# M55M1 register map
File version: 1.0
Registers are 32-bit, read-write, reset 0x0 unless marked. A register's access mark holds for its fields unless they carry their own. Offsets are from the block's base; [hi:lo] are bit positions; {n}, {i} and the like mark numbered series; 'fields as' and 'values as' point back to an identical list.

## CLK_NS — CLK Register Map
Base 0x50001000
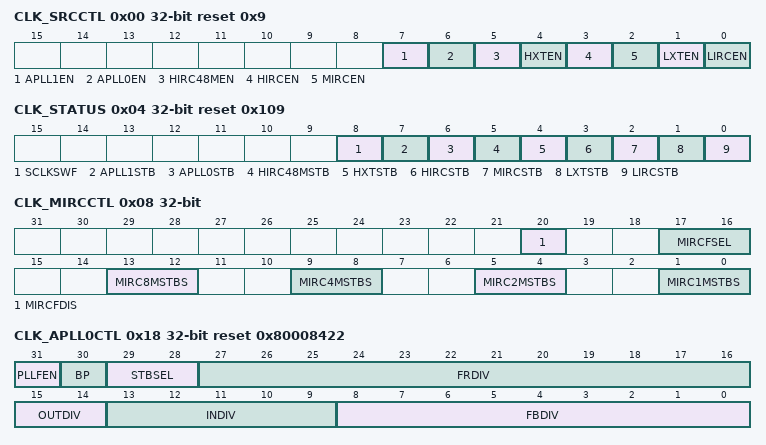
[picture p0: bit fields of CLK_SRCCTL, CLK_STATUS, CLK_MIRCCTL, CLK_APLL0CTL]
0x00 CLK_SRCCTL ro reset 0x9 — Clock Source Control Register
  [7] APLL1EN — APLL1 Enable Bit. Note : This bit is not retained when D2 power is turned off.
    0=APLL1 Disabled; 1=APLL1 Enabled
  [6] APLL0EN — APLL0 Enable Bit. Note : This bit is not retained when D2 power is turned off.
    0=APLL0 Disabled; 1=APLL0 Enabled
  [5] HIRC48MEN — HIRC48M Enable Bit. Note : This bit is not retained when D2 power is turned off.
    0=48 MHz internal high speed RC oscillator (HIRC48M) Disabled; 1=48 MHz internal high speed RC oscillator (HIRC48M) Enabled
  [4] HXTEN — HXT Enable Bit. Note : This bit is not retained when D2 power is turned off.
    0=4~32 MHz external high speed crystal (HXT) Disabled; 1=4~32 MHz external high speed crystal (HXT) Enabled
  [3] HIRCEN — HIRC Enable Bit. Note : This bit is not retained when D2 power is turned off.
    0=12 MHz internal high speed RC oscillator (HIRC) Disabled; 1=12 MHz internal high speed RC oscillator (HIRC) Enabled
  [2] MIRCEN — MIRC Enable Bit. Note : This bit is not retained when D2 power is turned off.
    0=1~8 MHz internal middle speed RC oscillator (MIRC) Disabled; 1=1~8 MHz internal middle speed RC oscillator (MIRC) Enabled
  [1] LXTEN — LXT Enable Bit. Note : This bit is not retained when D5 power is turned off.
    0=32.768 kHz external low speed crystal (LXT) Disabled; 1=32.768 kHz external low speed crystal (LXT) Enabled
  [0] LIRCEN — LIRC Enable Bit. Note : This bit is not retained when D4 power is turned off.
    0=32 kHz internal low speed RC oscillator (LIRC) Disabled; 1=32 kHz internal low speed RC oscillator (LIRC) Enabled
0x04 CLK_STATUS ro reset 0x109 — Clock Status Monitor Register
  [8] SCLKSWF — System Clock Switching Finish Flag (Read Only). This bit is updated when software switches system clock source. If switch target clock is stable, this bit will be set to 1. If switch target clock is not stable, this bit will be set to 0. Note 1: This bit is read only. After selected clock source is stable, hardware will switch system clock to selected clock automatically, and SCLKSWF will be setted automatically by hardware. Note 2: This bit is not retained when D0 power is turned off.
    0=Clock switching not finish; 1=Clock switching finish
  [7] APLL1STB — Internal APLL1 Clock Source Stable Flag (Read Only). Note: This bit is not retained when D0 power is turned off.
    0=Internal APLL1 clock is not stable or disabled; 1=Internal APLL1 clock is stable and enabled
  [6] APLL0STB — Internal APLL0 Clock Source Stable Flag (Read Only). Note: This bit is not retained when D0 power is turned off.
    0=Internal APLL0 clock is not stable or disabled; 1=Internal APLL0 clock is stable and enabled
  [5] HIRC48MSTB — HIRC48M Clock Source Stable Flag (Read Only). Note: This bit is not retained when D2 power is turned off.
    0=48 MHz internal high speed RC oscillator (HIRC48M) clock is not stable or disabled; 1=48 MHz internal high speed RC oscillator (HIRC48M) clock is stable and enabled
  [4] HXTSTB — HXT Clock Source Stable Flag (Read Only). Note: This bit is not retained when D2 power is turned off.
    0=4~32 MHz external high speed crystal oscillator (HXT) clock is not stable or disabled; 1=4~32 MHz external high speed crystal oscillator (HXT) clock is stable and enabled
  [3] HIRCSTB — HIRC Clock Source Stable Flag (Read Only). Note: This bit is not retained when D2 power is turned off.
    0=12 MHz internal high speed RC oscillator (HIRC) clock is not stable or disabled; 1=12 MHz internal high speed RC oscillator (HIRC) clock is stable and enabled
  [2] MIRCSTB — MIRC Clock Source Stable Flag (Read Only). Note: This bit is not retained when D2 power is turned off.
    0=Internal middle speed RC oscillator (MIRC) clock is not stable or disabled; 1=Internal middle speed RC oscillator (MIRC) clock is stable and enabled
  [1] LXTSTB — LXT Clock Source Stable Flag (Read Only). Note: This bit is not retained when D2 power is turned off.
    0=32.768 kHz external low speed crystal oscillator (LXT) clock is not stable or disabled; 1=32.768 kHz external low speed crystal oscillator (LXT) clock is stabled and enabled
  [0] LIRCSTB — LIRC Clock Source Stable Flag (Read Only). Note: This bit is not retained when D2 power is turned off.
    0=32 kHz internal low speed RC oscillator (LIRC) clock is not stable or disabled; 1=32 kHz internal low speed RC oscillator (LIRC) clock is stable and enabled
0x08 CLK_MIRCCTL ro — MIRC Control Register
  [20] MIRCFDIS — MIRC Clock Filter Disable Bit. Note: This bit is not retained when D2 power is turned off.
    0=MIRC Filter enabled; 1=MIRC Filter disabled
  [17:16] MIRCFSEL — MIRC Frequency Select Bits. Note: These bits are not retained when D2 power is turned off.
    0=Internal middle speed RC oscillator frequency is 1 MHz; 1=Internal middle speed RC oscillator frequency is 2 MHz; 2=Internal middle speed RC oscillator frequency is 4 MHz; 3=Internal middle speed RC oscillator frequency is 8 MHz
  [13:12] MIRC8MSTBS — MIRC8M Stable Count Select. Note: These bits are not retained when D2 power is turned off.
    0=MIRC8M stable count is 24 clocks and clock output deviation about 2%; 1=MIRC8M stable count is 21 clocks and clock output deviation about 5%
  [9:8] MIRC4MSTBS — MIRC4M Stable Count Select. Note: These bits are not retained when D2 power is turned off.
    0=MIRC4M stable count is 12 clocks and clock output deviation about 2%; 1=MIRC4M stable count is 10 clocks and clock output deviation about 5%
  [5:4] MIRC2MSTBS — MIRC2M Stable Count Select. Note: These bits are not retained when D2 power is turned off.
    0=MIRC2M stable count is 10 clocks and clock output deviation about 2%; 1=MIRC2M stable count is 6 clocks and clock output deviation about 5%
  [1:0] MIRC1MSTBS — MIRC1M Stable Count Select. Note: These bits are not retained when D2 power is turned off.
    0=MIRC1M stable count is 9 clocks and clock output deviation about 2%; 1=MIRC1M stable count is 8 clocks and clock output deviation about 5%
0x18 CLK_APLL0CTL ro reset 0x80008422 — APLL0 Control Register
  [31] PLLFEN — APLL0 Clock Filter Enable Bit. Note: This bit is not retained when D2 power is turned off.
    0=APLL0 Filter Disable; 1=APLL0 Filter Enable
  [30] BP — APLL0 Bypass Control. Note: This bit is not retained when D2 power is turned off.
    0=APLL0 is in normal mode (default); 1=APLL0 clock output is same as APLL0 input clock FIN
  [29:28] STBSEL — APLL0 Stable Counter Selection. Note: These bits are not retained when D2 power is turned off.
    0=APLL0 stable time is 820 APLL0 source clock (source clock is equal to 4M); 1=APLL0 stable time is 2460 APLL0 source clock (4 MHz source clock ≤12 MHz); 2=APLL0 stable time is 4920 APLL0 source clock (12 MHz source clock ≤24 MHz)
  [27:16] FRDIV — APLL0 Fractional Divider Control. Refer to the formulas below the table. Note: These bits are not retained when D2 power is turned off.
  [15:14] OUTDIV — APLL0 Output Divider Control. Refer to the formulas below the table. Note: These bits are not retained when D2 power is turned off.
  [13:9] INDIV — APLL0 Input Divider Control. Refer to the formulas below the table. Note: These bits are not retained when D2 power is turned off.
  [8:0] FBDIV — APLL0 Feedback Divider Control. Refer to the formulas below the table. Note: These bits are not retained when D2 power is turned off.
0x1C CLK_APLL0SEL ro — APLL0 Clock Source Select Control Register
  [1:0] APLLSRC — APLL0 Source Clock Selection. Note: These bits are not retained when D2 power is turned off.
    0=APLL0 source clock from 4~24 MHz external high-speed crystal oscillator (HXT); 1=APLL0 source clock from 24~32 MHz external high-speed crystal oscillator (HXT/2); 2=APLL0 source clock from 12 MHz internal high-speed oscillator (HIRC); 3=APLL0 source clock from 48 MHz internal high-speed oscillator (HIRC48M/4)
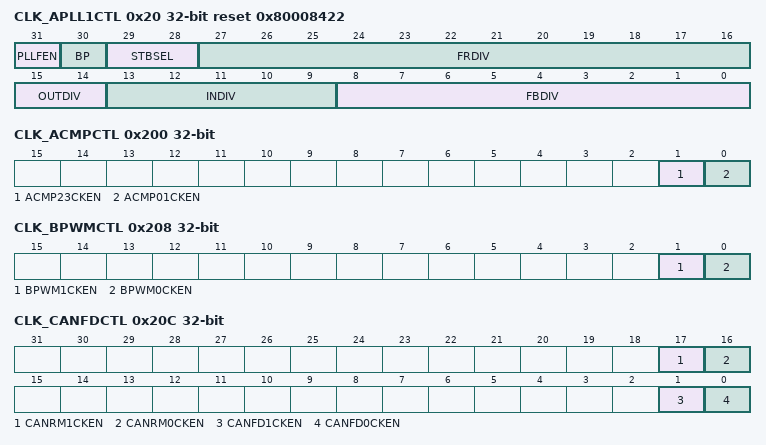
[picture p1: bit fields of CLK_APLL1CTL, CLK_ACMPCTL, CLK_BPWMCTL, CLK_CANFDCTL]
0x20 CLK_APLL1CTL ro reset 0x80008422 — APLL1 Control Register
  [31] PLLFEN — APLL1 Clock Filter Enable Bit. Note: This bit is not retained when D2 power is turned off.
    0=APLL1 Filter Disable; 1=APLL1 Filter Enable
  [30] BP — APLL1 Bypass Control. Note: This bit is not retained when D2 power is turned off.
    0=APLL1 is in normal mode (default); 1=APLL1 clock output is same as APLL1 input clock FIN
  [29:28] STBSEL — APLL1 Stable Counter Selection. Note 1: These bits are not retained when D2 power is turned off.
    0=APLL1 stable time is 820 APLL1 source clock (source clock is equal to 4M); 1=APLL1 stable time is 2460 APLL1 source clock (4 MHz source clock ≤12 MHz); 2=APLL1 stable time is 4920 APLL1 source clock (12 MHz source clock ≤24 MHz)
  [27:16] FRDIV — APLL1 Fractional Divider Control. Refer to the formulas below the table. Note: These bits are not retained when D2 power is turned off.
  [15:14] OUTDIV — APLL1 Output Divider Control. Refer to the formulas below the table. Note: These bits are not retained when D2 power is turned off.
  [13:9] INDIV — APLL1 Input Divider Control. Refer to the formulas below the table. Note: These bits are not retained when D2 power is turned off.
  [8:0] FBDIV — APLL1 Feedback Divider Control. Refer to the formulas below the table. Note: These bits are not retained when D2 power is turned off.
0x24 CLK_APLL1SEL ro — APLL1 Clock Source Select Control Register
  [1:0] APLLSRC — APLL1 Source Clock Selection. Note : These bits are not retained when D2 power is turned off.
    0=APLL1 source clock from 4~24 MHz external high-speed crystal oscillator (HXT); 1=APLL1 source clock from 24~32 MHz external high-speed crystal oscillator (HXT/2); 2=APLL1 source clock from 12 MHz internal high-speed oscillator (HIRC); 3=APLL1 source clock from 48 MHz internal high-speed oscillator (HIRC48M/4)
0x200 CLK_ACMPCTL ro — ACMP Clock Enable Control Register
  [1] ACMP23CKEN — ACMP2/3 Clock Enable Bit. Note: This bit is not retained when D0 power is turned off.
    0=ACMP2/3 clock Disabled; 1=ACMP2/3 clock Enabled
  [0] ACMP01CKEN — ACMP0/1 Clock Enable Bit. Note: This bit is not retained when D0 power is turned off.
    0=ACMP0/1 clock Disabled; 1=ACMP0/1 clock Enabled
0x204 CLK_AWFCTL ro — AWF Clock Enable Control Register
  [0] AWF0CKEN — AWFx Clock Enable Bit. Note: This bit is not retained when D0 power is turned off.
    0=AWFx clock Disabled; 1=AWFx clock Enabled
0x208 CLK_BPWMCTL ro — BPWM Clock Enable Control Register
  [1] BPWM1CKEN — BPWMx Clock Enable Bit. Note: This bit is not retained when D0 power is turned off.
    0=BPWMx clock Disabled; 1=BPWMx clock Enabled
  [0] BPWM0CKEN — BPWMx Clock Enable Bit. Note: This bit is not retained when D0 power is turned off.
    0=BPWMx clock Disabled; 1=BPWMx clock Enabled
0x20C CLK_CANFDCTL ro — CANFD Clock Enable Control Register
  [17] CANRM1CKEN — CANFD1 Message SRAM Clock Enable Bit. Note: This bit is not retained when D0 power is turned off.
    0=CANFD1 Message SRAM clock Disabled; 1=CANFD1 Message SRAM clock Enabled
  [16] CANRM0CKEN — CANFD0 Message SRAM Clock Enable Bit. Note: This bit is not retained when D0 power is turned off.
    0=CANFD0 Message SRAM clock Disabled; 1=CANFD0 Message SRAM clock Enabled
  [1] CANFD1CKEN — CANFDx Clock Enable Bit. Note: This bit is not retained when D0 power is turned off.
    0=CANFDx clock Disabled; 1=CANFDx clock Enabled
  [0] CANFD0CKEN — CANFDx Clock Enable Bit. Note: This bit is not retained when D0 power is turned off.
    0=CANFDx clock Disabled; 1=CANFDx clock Enabled
0x210 CLK_CCAPCTL ro — CCAP Clock Enable Control Register
  [0] CCAP0CKEN — CCAPx Clock Enable Bit. Note: This bit is not retained when D0 power is turned off.
    0=CCAPx clock Disabled; 1=CCAPx clock Enabled
0x214 CLK_CRCCTL ro — CRC Clock Enable Control Register
  [0] CRC0CKEN — CRCx Clock Enable Bit. Note: This bit is not retained when D0 power is turned off.
    0=CRCx clock Disabled; 1=CRCx clock Enabled
0x218 CLK_CRYPTOCTL ro — CRYPTO Clock Enable Control Register
  [0] CRYPTO0CKEN — CRYPTOx Clock Enable Bit. Note: This bit is not retained when D0 power is turned off.
    0=CRYPTOx clock Disabled; 1=CRYPTOx clock Enabled
0x21C CLK_DACCTL ro — DAC Clock Enable Control Register
  [0] DAC01CKEN — DAC0/DAC1 Clock Enable Bit. Note: This bit is not retained when D0 power is turned off.
    0=DAC0/1 clock Disabled; 1=DAC0/1 clock Enabled
0x220 CLK_DMICCTL ro — DMIC Clock Enable Control Register
  [0] DMIC0CKEN — DMICx Clock Enable Bit. Note: This bit is not retained when D2 power is turned off.
    0=DMICx clock Disabled; 1=DMICx clock Enabled
0x224 CLK_EADCCTL ro — EADC Clock Enable Control Register
  [0] EADC0CKEN — EADCx Clock Enable Bit. Note: This bit is not retained when D0 power is turned off.
    0=EADCx clock Disabled; 1=EADCx clock Enabled
0x228 CLK_EBICTL ro — EBI Clock Enable Control Register
  [0] EBI0CKEN — EBIx Clock Enable Bit. Note: This bit is not retained when D0 power is turned off.
    0=EBIx clock Disabled; 1=EBIx clock Enabled
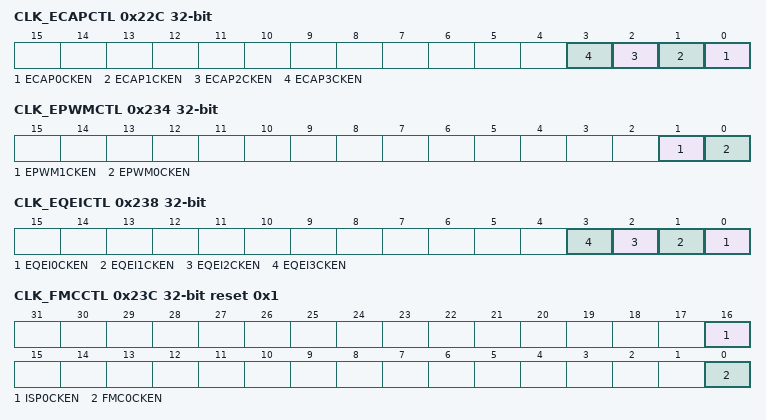
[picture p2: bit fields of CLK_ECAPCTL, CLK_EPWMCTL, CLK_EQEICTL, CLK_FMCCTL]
0x22C CLK_ECAPCTL ro — ECAP Clock Enable Control Register
  [all] fields
    0=ECAPx clock Disabled; 1=ECAPx clock Enabled
  [n] ECAP{n}CKEN (n=0..3) — ECAPx Clock Enable Bit. Note: This bit is not retained when D0 power is turned off.
0x230 CLK_EMACCTL ro — EMAC Clock Enable Control Register
  [0] EMAC0CKEN — EMACx Clock Enable Bit. Note: This bit is not retained when D0 power is turned off.
    0=EMACx clock Disabled; 1=EMACx clock Enabled
0x234 CLK_EPWMCTL ro — EPWM Clock Enable Control Register
  [1] EPWM1CKEN — EPWMx Clock Enable Bit. Note: This bit is not retained when D0 power is turned off.
    0=EPWMx clock Disabled; 1=EPWMx clock Enabled
  [0] EPWM0CKEN — EPWMx Clock Enable Bit. Note: This bit is not retained when D0 power is turned off.
    0=EPWMx clock Disabled; 1=EPWMx clock Enabled
0x238 CLK_EQEICTL ro — EQEI Clock Enable Control Register
  [all] fields
    0=EQEIx clock Disabled; 1=EQEIx clock Enabled
  [n] EQEI{n}CKEN (n=0..3) — EQEIx Clock Enable Bit. Note: This bit is not retained when D0 power is turned off.
0x23C CLK_FMCCTL ro reset 0x1 — FMC Clock Enable Control Register
  [16] ISP0CKEN — ISPx Clock Enable Bit. Note: This bit is not retained when D0 power is turned off.
    0=ISPx clock Disabled; 1=ISPx clock Enabled
  [0] FMC0CKEN — FMCx Clock Enable Bit. Note: This bit is not retained when D0 power is turned off.
    0=FMC clock Disabled when chip is under IDLE mode; 1=FMC clock Enabled when chip is under IDLE mode
0x240 CLK_GDMACTL ro — GDMA Clock Enable Control Register
  [0] GDMA0CKEN — GDMAx Clock Enable Bit. Note: This bit is not retained when D0 power is turned off.
    0=GDMAx clock Disabled; 1=GDMAx clock Enabled
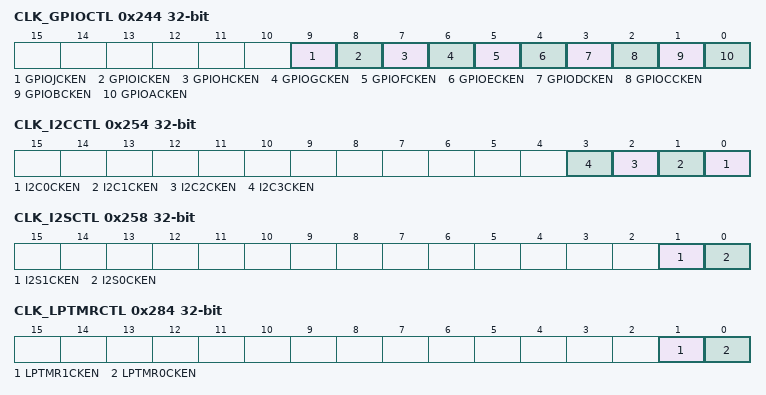
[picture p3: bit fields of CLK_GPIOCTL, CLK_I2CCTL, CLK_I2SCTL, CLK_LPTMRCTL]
0x244 CLK_GPIOCTL ro — GPIO Clock Enable Control Register
  [9] GPIOJCKEN — GPIOJ Clock Enable Bit. Note: This bit is not retained when D0 power is turned off.
    0=GPIOJ clock Disabled; 1=GPIOJ clock Enabled
  [8] GPIOICKEN — GPIOI Clock Enable Bit. Note: This bit is not retained when D0 power is turned off.
    0=GPIOI clock Disabled; 1=GPIOI clock Enabled
  [7] GPIOHCKEN — GPIOH Clock Enable Bit. Note: This bit is not retained when D0 power is turned off.
    0=GPIOH clock Disabled; 1=GPIOH clock Enabled
  [6] GPIOGCKEN — GPIOG Clock Enable Bit. Note: This bit is not retained when D0 power is turned off.
    0=GPIOG clock Disabled; 1=GPIOG clock Enabled
  [5] GPIOFCKEN — GPIOF Clock Enable Bit. Note: This bit is not retained when D0 power is turned off.
    0=GPIOF clock Disabled; 1=GPIOF clock Enabled
  [4] GPIOECKEN — GPIOE Clock Enable Bit. Note: This bit is not retained when D0 power is turned off.
    0=GPIOE clock Disabled; 1=GPIOE clock Enabled
  [3] GPIODCKEN — GPIOD Clock Enable Bit. Note: This bit is not retained when D0 power is turned off.
    0=GPIOD clock Disabled; 1=GPIOD clock Enabled
  [2] GPIOCCKEN — GPIOC Clock Enable Bit. Note: This bit is not retained when D0 power is turned off.
    0=GPIOC clock Disabled; 1=GPIOC clock Enabled
  [1] GPIOBCKEN — GPIOB Clock Enable Bit. Note: This bit is not retained when D0 power is turned off.
    0=GPIOB clock Disabled; 1=GPIOB clock Enabled
  [0] GPIOACKEN — GPIOA Clock Enable Bit. Note: This bit is not retained when D0 power is turned off.
    0=GPIOA clock Disabled; 1=GPIOA clock Enabled
0x248 CLK_HSOTGCTL ro — HSOTG Clock Enable Control Register
  [0] HSOTG0CKEN — HSOTGx Clock Enable Bit. Note: This bit is not retained when D0 power is turned off.
    0=HSOTGx clock Disabled; 1=HSOTGx clock Enabled
0x24C CLK_HSUSBDCTL ro — HSUSBD Clock Enable Control Register
  [0] HSUSBD0CKEN — HSUSBDx Clock Enable Bit. Note: This bit is not retained when D0 power is turned off.
    0=HSUSBDx clock Disabled; 1=HSUSBDx clock Enabled
0x250 CLK_HSUSBHCTL ro — HSUSBH Clock Enable Control Register
  [0] HSUSBH0CKEN — HSUSBHx Clock Enable Bit. Note: This bit is not retained when D0 power is turned off.
    0=HSUSBHx clock Disabled; 1=HSUSBHx clock Enabled
0x254 CLK_I2CCTL ro — I2C Clock Enable Control Register
  [all] fields
    0=I2Cx clock Disabled; 1=I2Cx clock Enabled
  [n] I2C{n}CKEN (n=0..3) — I2Cx Clock Enable Bit. Note: This bit is not retained when D0 power is turned off.
0x258 CLK_I2SCTL ro — I2S Clock Enable Control Register
  [1] I2S1CKEN — I2Sx Clock Enable Bit. Note: This bit is not retained when D0 power is turned off.
    0=I2Sx clock Disabled; 1=I2Sx clock Enabled
  [0] I2S0CKEN — I2Sx Clock Enable Bit. Note: This bit is not retained when D0 power is turned off.
    0=I2Sx clock Disabled; 1=I2Sx clock Enabled
0x25C CLK_I3CCTL ro — I3C Clock Enable Control Register
  [0] I3C0CKEN — I3Cx Clock Enable Bit. Note: This bit is not retained when D0 power is turned off.
    0=I3Cx clock Disabled; 1=I3Cx clock Enabled
0x260 CLK_KDFCTL ro — KDF Clock Enable Control Register
  [0] KDF0CKEN — KDFx Clock Enable Bit. Note: This bit is not retained when D0 power is turned off.
    0=KDFx clock Disabled; 1=KDFx clock Enabled
0x264 CLK_KPICTL ro — KPI Clock Enable Control Register
  [0] KPI0CKEN — KPIx Clock Enable Bit. Note: This bit is not retained when D0 power is turned off.
    0=KPIx clock Disabled; 1=KPIx clock Enabled
0x268 CLK_KSCTL ro — KS Clock Enable Control Register
  [0] KS0CKEN — KSx Clock Enable Bit. Note: This bit is not retained when D0 power is turned off.
    0=KSx clock Disabled; 1=KSx clock Enabled
0x26C CLK_LPADCCTL ro — Low Power ADC Clock Enable Control Register
  [0] LPADC0CKEN — LPADCx Clock Enable Bit. Note: This bit is not retained when D0 power is turned off.
    0=LPADCx clock Disabled; 1=LPADCx clock Enabled
0x270 CLK_LPPDMACTL ro — Low Power PDMA Clock Enable Control Register
  [0] LPPDMA0CKEN — LPPDMAx Clock Enable Bit. Note: This bit is not retained when D0 power is turned off.
    0=LPPDMAx clock Disabled; 1=LPPDMAx clock Enabled
0x274 CLK_LPGPIOCTL ro — Low Power GPIO Clock Enable Control Register
  [0] LPGPIO0CKEN — LPGPIOx Clock Enable Bit. Note: This bit is not retained when D0 power is turned off.
    0=LPGPIOx clock Disabled; 1=LPGPIOx clock Enabled
0x278 CLK_LPI2CCTL ro — Low Power I2C Clock Enable Control Register
  [0] LPI2C0CKEN — LPI2Cx Clock Enable Bit. Note: This bit is not retained when D0 power is turned off.
    0=LPI2Cx clock Disabled; 1=LPI2Cx clock Enabled
0x27C CLK_LPSPICTL ro — Low Power SPI Clock Enable Control Register
  [0] LPSPI0CKEN — LPSPIx Clock Enable Bit. Note: This bit is not retained when D0 power is turned off.
    0=LPSPIx clock Disabled; 1=LPSPIx clock Enabled
0x280 CLK_LPSRAMCTL ro — Low Power SRAM Clock Enable Control Register
  [0] LPSRAM0CKEN — LPSRAMx Clock Enable Bit. Note: This bit is not retained when D0 power is turned off.
    0=LPSRAMx clock Disabled; 1=LPSRAMx clock Enabled
0x284 CLK_LPTMRCTL ro — Low Power Timer Clock Enable Control Register
  [1] LPTMR1CKEN — LPTMRx Clock Enable Bit. Note: This bit is not retained when D0 power is turned off.
    0=LPTMRx clock Disabled; 1=LPTMRx clock Enabled
  [0] LPTMR0CKEN — LPTMRx Clock Enable Bit. Note: This bit is not retained when D0 power is turned off.
    0=LPTMRx clock Disabled; 1=LPTMRx clock Enabled
0x288 CLK_LPUARTCTL ro — Low Power UART Clock Enable Control Register
  [0] LPUART0CKEN — LPUARTx Clock Enable Bit. Note: This bit is not retained when D0 power is turned off.
    0=LPUARTx clock Disabled; 1=LPUARTx clock Enabled
0x28C CLK_NPUCTL ro — NPU Clock Enable Control Register
  [0] NPU0CKEN — NPUx Clock Enable Bit. Note: This bit is not retained when D0 power is turned off.
    0=NPUx clock Disabled; 1=NPUx clock Enabled
0x294 CLK_OTFCCTL ro — OTFC Clock Enable Control Register
  [0] OTFC0CKEN — OTFCx Clock Enable Bit. Note: This bit is not retained when D0 power is turned off.
    0=OTFCx clock Disabled; 1=OTFCx clock Enabled
0x298 CLK_OTGCTL ro — OTG Clock Enable Control Register
  [0] OTG0CKEN — OTGx Clock Enable Bit. Note: This bit is not retained when D0 power is turned off.
    0=OTGx clock Disabled; 1=OTGx clock Enabled
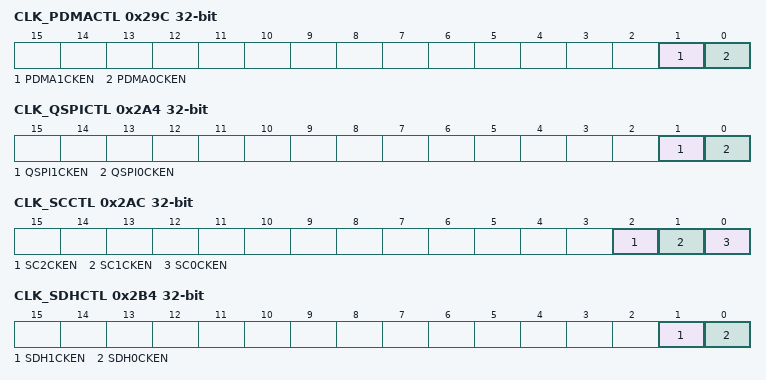
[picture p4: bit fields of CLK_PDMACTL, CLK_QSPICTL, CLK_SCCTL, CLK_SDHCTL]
0x29C CLK_PDMACTL ro — PDMA Clock Enable Control Register
  [1] PDMA1CKEN — PDMAx Clock Enable Bit. Note: This bit is not retained when D0 power is turned off.
    0=PDMAx clock Disabled; 1=PDMAx clock Enabled
  [0] PDMA0CKEN — PDMAx Clock Enable Bit. Note: This bit is not retained when D0 power is turned off.
    0=PDMAx clock Disabled; 1=PDMAx clock Enabled
0x2A0 CLK_PSIOCTL ro — PSIO Clock Enable Control Register
  [0] PSIO0CKEN — PSIOx Clock Enable Bit. Note: This bit is not retained when D0 power is turned off.
    0=PSIOx clock Disabled; 1=PSIOx clock Enabled
0x2A4 CLK_QSPICTL ro — QSPI Clock Enable Control Register
  [1] QSPI1CKEN — QSPIx Clock Enable Bit. Note: This bit is not retained when D0 power is turned off.
    0=QSPIx clock Disabled; 1=QSPIx clock Enabled
  [0] QSPI0CKEN — QSPIx Clock Enable Bit. Note: This bit is not retained when D0 power is turned off.
    0=QSPIx clock Disabled; 1=QSPIx clock Enabled
0x2A8 CLK_RTCCTL ro — RTC Clock Enable Control Register
  [0] RTC0CKEN — RTCx Clock Enable Bit. Note: This bit is not retained when D0 power is turned off.
    0=RTCx clock Disabled; 1=RTCx clock Enabled
0x2AC CLK_SCCTL ro — SC Clock Enable Control Register
  [all] fields
    0=SCx clock Disabled; 1=SCx clock Enabled
  [2] SC2CKEN — SCx Clock Enable Bit. Note: This bit is not retained when D0 power is turned off.
  [1] SC1CKEN — SCx Clock Enable Bit. Note: This bit is not retained when D0 power is turned off.
  [0] SC0CKEN — SCx Clock Enable Bit. Note: This bit is not retained when D0 power is turned off.
0x2B0 CLK_SCUCTL ro reset 0x1 — SCU Clock Enable Control Register
  [0] SCU0CKEN — SCUx Clock Enable Bit. Note: This bit is not retained when D0 power is turned off.
    0=SCUx clock Disabled; 1=SCUx clock Enabled
0x2B4 CLK_SDHCTL ro — SDH Clock Enable Control Register
  [1] SDH1CKEN — SDHx Clock Enable Bit. Note: This bit is not retained when D0 power is turned off.
    0=SDHx clock Disabled; 1=SDHx clock Enabled
  [0] SDH0CKEN — SDHx Clock Enable Bit. Note: This bit is not retained when D0 power is turned off.
    0=SDHx clock Disabled; 1=SDHx clock Enabled
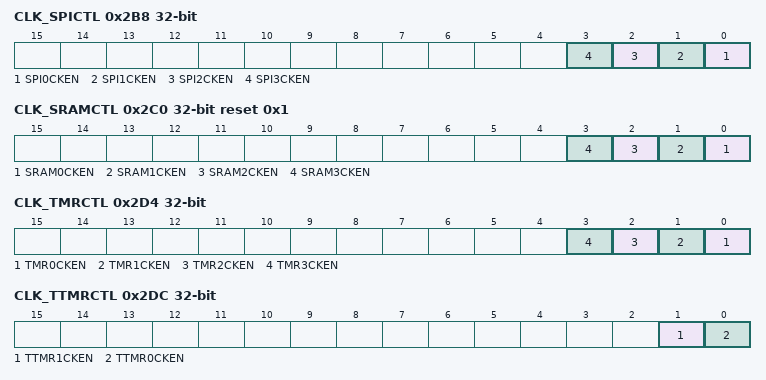
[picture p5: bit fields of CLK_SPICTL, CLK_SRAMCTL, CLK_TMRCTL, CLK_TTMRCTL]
0x2B8 CLK_SPICTL ro — SPI Clock Enable Control Register
  [all] fields
    0=SPIx clock Disabled; 1=SPIx clock Enabled
  [n] SPI{n}CKEN (n=0..3) — SPIx Clock Enable Bit. Note: This bit is not retained when D0 power is turned off.
0x2BC CLK_SPIMCTL ro — SPIM Clock Enable Control Register
  [0] SPIM0CKEN — SPIMx Clock Enable Bit. Note: This bit is not retained when D0 power is turned off.
    0=SPIMx clock Disabled; 1=SPIMx clock Enabled
0x2C0 CLK_SRAMCTL ro reset 0x1 — System SRAM Clock Enable Control Register
  [all] fields
    0=SRAMx clock Disabled; 1=SRAMx clock Enabled
  [n] SRAM{n}CKEN (n=0..3) — SRAMx Clock Enable Bit. Note: This bit is not retained when D0 power is turned off.
0x2CC CLK_STCTL ro — System Tick Clock Enable Control Register
  [0] ST0CKEN — SYSTICKx Clock Enable Bit. Note: This bit is not retained when D0 power is turned off.
    0=SYSTICKx clock Disabled; 1=SYSTICKx clock Enabled
0x2D4 CLK_TMRCTL ro — Timer Clock Enable Control Register
  [all] fields
    0=TIMERx clock Disabled; 1=TIMERx clock Enabled
  [n] TMR{n}CKEN (n=0..3) — TIMERx Clock Enable Bit. Note: This bit is not retained when D0 power is turned off.
0x2D8 CLK_TRNGCTL ro — TRNG Clock Enable Control Register
  [0] TRNG0CKEN — TRNGx Clock Enable Bit. Note: This bit is not retained when D0 power is turned off.
    0=TRNGx clock Disabled; 1=TRNGx clock Enabled
0x2DC CLK_TTMRCTL ro — Tick Timer Clock Enable Control Register
  [1] TTMR1CKEN — TTMRx Clock Enable Bit. Note: This bit is not retained when D2 power is turned off.
    0=TTMRx clock Disabled; 1=TTMRx clock Enabled
  [0] TTMR0CKEN — TTMRx Clock Enable Bit. Note: This bit is not retained when D2 power is turned off.
    0=TTMRx clock Disabled; 1=TTMRx clock Enabled
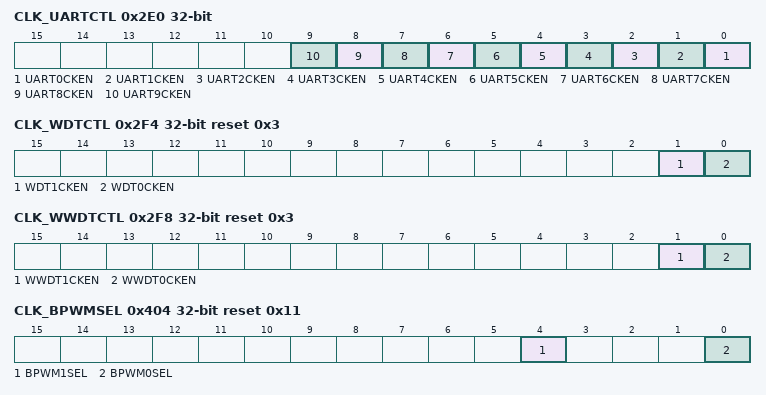
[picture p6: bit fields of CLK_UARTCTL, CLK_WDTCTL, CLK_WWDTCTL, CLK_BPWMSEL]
0x2E0 CLK_UARTCTL ro — UART Clock Enable Control Register
  [all] fields
    0=UARTx clock Disabled; 1=UARTx clock Enabled
  [n] UART{n}CKEN (n=0..9) — UARTx Clock Enable Bit. Note: This bit is not retained when D0 power is turned off.
0x2E4 CLK_USBDCTL ro — USBD Clock Enable Control Register
  [0] USBD0CKEN — USBDx Clock Enable Bit. Note: This bit is not retained when D0 power is turned off.
    0=USBDx clock Disabled; 1=USBDx clock Enabled
0x2E8 CLK_USBHCTL ro — USBH Clock Enable Control Register
  [0] USBH0CKEN — USBHx Clock Enable Bit. Note: This bit is not retained when D0 power is turned off.
    0=USBHx clock Disabled; 1=USBHx clock Enabled
0x2EC CLK_USCICTL ro — USCI Clock Enable Control Register
  [0] USCI0CKEN — USCIx Clock Enable Bit. Note: This bit is not retained when D0 power is turned off.
    0=USCIx clock Disabled; 1=USCIx clock Enabled
0x2F0 CLK_UTCPDCTL ro — UTCPD Clock Enable Control Register
  [0] UTCPD0CKEN — UTCPDx Clock Enable Bit. Note: This bit is not retained when D0 power is turned off.
    0=UTCPDx clock Disabled; 1=UTCPDx clock Enabled
0x2F4 CLK_WDTCTL ro reset 0x3 — WDT Clock Enable Control Register
  [1] WDT1CKEN — WDTx Clock Enable Bit. Note 2: This bit is not retained when D2 power is turned off.
    0=WDTx clock Disabled; 1=WDTx clock Enabled
  [0] WDT0CKEN — WDTx Clock Enable Bit. Note 2: This bit is not retained when D2 power is turned off.
    0=WDTx clock Disabled; 1=WDTx clock Enabled
0x2F8 CLK_WWDTCTL ro reset 0x3 — WWDT Clock Enable Control Register
  [1] WWDT1CKEN — WWDTx Clock Enable Bit. Note 2: This bit is not retained when D0 power is turned off.
    0=WWDTx clock Disabled; 1=WWDTx clock Enabled
  [0] WWDT0CKEN — WWDTx Clock Enable Bit. Note 2: This bit is not retained when D0 power is turned off.
    0=WWDTx clock Disabled; 1=WWDTx clock Enabled
0x400 CLK_SCLKSEL ro — System Clock Source Select Control Register
  [2:0] SCLKSEL — System Clock Source Selection. The system clock source is defined by SCLKSEL. Note: These bits are not retained when D2 power is turned off.
    0=Clock source from HIRC; 1=Clock source from MIRC; 2=Clock source from HIRC48M; 3=Clock source from HXT; 4=Clock source from APLL0
0x404 CLK_BPWMSEL ro reset 0x11 — BPWM Clock Source Select Control Register
  [4] BPWM1SEL — BPWM1 Clock Source Selection. The peripheral clock source of BPWM1 is defined by BPWM1SEL. Note: This bit is not retained when D1 power is turned off.
    0=Clock source from PCLK2; 1=Clock source from HCLK0
  [0] BPWM0SEL — BPWM0 Clock Source Selection. The peripheral clock source of BPWM0 is defined by BPWM0SEL. Note: This bit is not retained when D1 power is turned off.
    0=Clock source from PCLK0; 1=Clock source from HCLK0
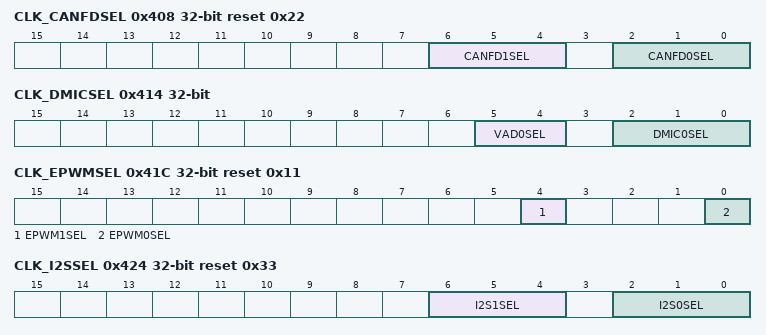
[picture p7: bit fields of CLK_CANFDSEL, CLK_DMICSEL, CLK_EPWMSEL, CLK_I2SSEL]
0x408 CLK_CANFDSEL ro reset 0x22 — CANFD Clock Source Select Control Register
  [6:4] CANFD1SEL — CANFD1 Clock Source Selection. The peripheral clock source of CANFD1 is defined by CANFD1SEL. Note: These bits are not retained when D1 power is turned off.
    0=Clock source from HXT; 1=Clock source from APLL0/2; 2=Clock source from HCLK0; 3=Clock source from HIRC; 4=Clock source from HIRC48M/4
  [2:0] CANFD0SEL — CANFD0 Clock Source Selection. The peripheral clock source of CANFD0 is defined by CANFD0SEL. Note: These bits are not retained when D1 power is turned off.
    values as CANFD1SEL
0x40C CLK_CCAPSEL ro reset 0x1 — CCAP Clock Source Select Control Register
  [2:0] CCAP0SEL — CCAP Sensor Clock Source Selection. The peripheral clock source of CCAP is defined by CCAP0SEL. Note: These bits are not retained when D2 power is turned off.
    0=Clock source from MIRC; 1=Clock source from HCLK2; 2=Clock source from HIRC; 3=Clock source from APLL0/2; 4=Clock source from HXT
0x410 CLK_CLKOSEL ro — Clock Output Clock Source Select Control Register
  [3:0] CLKOSEL — Clock Output Clock Source Selection. Note: These bits are not retained when D2 power is turned off.
    0=Clock source from SCLK; 1=Clock source from ACLK; 2=Clock source from HCLK0; 3=Clock source from HCLK1; 4=Clock source from HCLK2; 5=Clock source from APLL0/2; 6=Clock source from APLL1/2; 7=Clock source from HIRC48M; 8=Clock source from HXT; 9=Clock source from HIRC; 10=Clock source from MIRC; 11=Clock source from LXT; 12=Clock source from LIRC
0x414 CLK_DMICSEL ro — DMIC Clock Source Select Control Register
  [5:4] VAD0SEL — VAD Clock Source Selection. The peripheral clock VAD source of DIMC0 is defined by VAD0SEL. Note: These bits are not retained when D2 power is turned off.
    0=Clock source from PCLK4; 1=Clock source from MIRC; 2=Clock source from HIRC
  [2:0] DMIC0SEL — DMIC Clock Source Selection. The peripheral clock source of DIMC0 is defined by DMIC0SEL. Note: These bits are not retained when D2 power is turned off.
    0=Clock source from HXT; 1=Clock source from APLL1/2; 2=Clock source from MIRC; 3=Clock source from HIRC; 4=Clock source from HIRC48M; 5=Clock source from PCLK4
0x418 CLK_EADCSEL ro reset 0x2 — EADC Clock Source Select Control Register
  [1:0] EADC0SEL — EADC0 Clock Source Selection. The peripheral clock source of EADC0 is defined by EADC0SEL. Note: These bits are not retained when D1 power is turned off.
    0=Clock source from APLL1/2; 1=Clock source from APLL0/2; 2=PCLK0
0x41C CLK_EPWMSEL ro reset 0x11 — EPWM Clock Source Select Control Register
  [4] EPWM1SEL — EPWM1 Clock Source Selection. The peripheral clock source of EPWM1 is defined by EPWM1SEL. Note: This bit is not retained when D1 power is turned off.
    0=Clock source from PCLK2; 1=Clock source from HCLK0
  [0] EPWM0SEL — EPWM0 Clock Source Selection. The peripheral clock source of EPWM0 is defined by EPWM0SEL. Note: This bit is not retained when D1 power is turned off.
    0=Clock source from PCLK0; 1=Clock source from HCLK0
0x420 CLK_FMCSEL ro — FMC Clock Source Select Control Register
  [0] FMC0SEL — FMC0 Clock Source Selection. The peripheral clock source of FMC0 is defined by FMC0SEL. Note: This bit is not retained when D0 power is turned off.
    0=Clock source from HIRC; 1=Clock source from HIRC48M/4
0x424 CLK_I2SSEL ro reset 0x33 — I2S Clock Source Select Control Register
  [6:4] I2S1SEL — I2S1 Clock Source Selection (Write Protect). The peripheral clock source of I2S1 is defined by I2S1SEL. Note: These bits are not retained when D1 power is turned off.
    0=Clock source from HXT; 1=Clock source from APLL1/2; 2=Clock source from APLL0/2; 3=Clock source from PCLK3; 4=Clock source from HIRC; 5=Clock source from HIRC48M
  [2:0] I2S0SEL — I2S0 Clock Source Selection (Write Protect). The peripheral clock source of I2S0 is defined by I2S0SEL. Note: These bits are not retained when D1 power is turned off.
    0=Clock source from HXT; 1=Clock source from APLL1/2; 2=Clock source from APLL0/2; 3=Clock source from PCLK1; 4=Clock source from HIRC; 5=Clock source from HIRC48M
0x428 CLK_I3CSEL ro — I3C Clock Source Select Control Register
  [0] I3C0SEL — I3C0 Clock Source Selection (Write Protect). The peripheral clock source of I3C0 is defined by I3C0SEL. Note: This bit is not retained when D1 power is turned off.
    0=Clock source from HCLK0; 1=Clock source from APLL1/2
0x42C CLK_KPISEL ro — KPI Clock Source Select Control Register
  [1:0] KPI0SEL — KPI0 Clock Source Selection (Write Protect). The peripheral clock source of KPI0 is defined by KPI0SEL. Note: These bits are not retained when D1 power is turned off.
    0=Clock source from HIRC48M/4; 1=Clock source from HIRC; 2=Clock source from LIRC; 3=Clock source from HXT
0x430 CLK_LPADCSEL ro — Low Power ADC Clock Source Select Control Register
  [1:0] LPADC0SEL — LPADC0 Clock Source Selection. The peripheral clock source of LPADC0 is defined by LPADC0SEL. Note: These bits are not retained when D2 power is turned off.
    0=Clock source from PCLK4; 1=Clock source from LXT; 2=Clock source from MIRC; 3=Clock source from HIRC
0x434 CLK_LPSPISEL ro — Low Power SPI Clock Source Select Control Register
  [1:0] LPSPI0SEL — LPSPI0 Clock Source Selection. The peripheral clock source of LPSPI0 is defined by LPSPI0SEL. Note: These bits are not retained when D2 power is turned off.
    values as CLK_DMICSEL.VAD0SEL
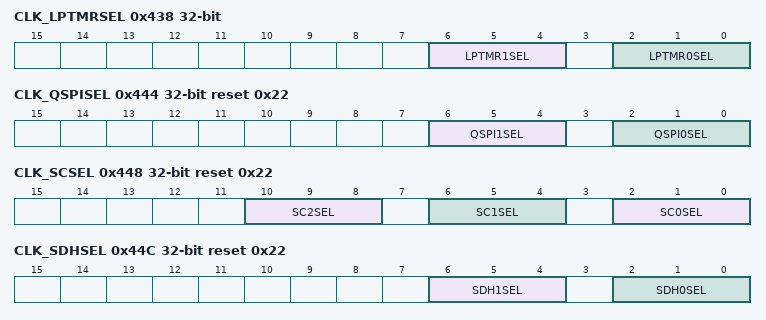
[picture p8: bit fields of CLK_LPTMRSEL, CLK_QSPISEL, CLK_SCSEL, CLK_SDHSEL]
0x438 CLK_LPTMRSEL ro — Low Power Timer Clock Source Select Control Register
  [6:4] LPTMR1SEL — LPTMR1 Clock Source Selection. The peripheral clock source of LPTMR1 is defined by LPTMR1SEL. Note: These bits are not retained when D2 power is turned off.
    0=Clock source from PCLK4; 1=Clock source from LXT; 2=Clock source from LIRC; 3=Clock source from MIRC; 4=Clock source from HIRC; 5=Clock source from external clock TM1 pin
  [2:0] LPTMR0SEL — LPTMR0 Clock Source Selection. The peripheral clock source of LPTMR0 is defined by LPTMR0SEL. Note: These bits are not retained when D2 power is turned off.
    0=Clock source from PCLK4; 1=Clock source from LXT; 2=Clock source from LIRC; 3=Clock source from MIRC; 4=Clock source from HIRC; 5=Clock source from external clock TM0 pin
0x43C CLK_LPUARTSEL ro — Low Power UART Clock Source Select Control Register
  [1:0] LPUART0SEL — LPUART0 Clock Source Selection. The peripheral clock source of LPUART0 is defined by LPUART0SEL. Note: These bits are not retained when D2 power is turned off.
    values as CLK_LPADCSEL.LPADC0SEL
0x440 CLK_PSIOSEL ro reset 0x5 — PSIO Clock Source Select Control Register
  [2:0] PSIO0SEL — PSIO0 Clock Source Selection. The peripheral clock source of PSIO0 is defined by PSIO0SEL. Note: These bits are not retained when D1 power is turned off.
    0=Clock source from LXT; 1=Clock source from HXT; 2=Clock source from LIRC; 3=Clock source from HIRC; 4=Clock source from HIRC48M/4; 5=Clock source from PCLK1; 6=Clock source from APLL0/2
0x444 CLK_QSPISEL ro reset 0x22 — QSPI Clock Source Select Control Register
  [6:4] QSPI1SEL — QSPI1 Clock Source Selection. The peripheral clock source of QSPI1 is defined by QSPI1SEL. Note: These bits are not retained when D1 power is turned off.
    0=Clock source from HXT; 1=Clock source from APLL0/2; 2=Clock source from PCLK2; 3=Clock source from HIRC; 4=Clock source from HIRC48M/4
  [2:0] QSPI0SEL — QSPI0 Clock Source Selection. The peripheral clock source of QSPI0 is defined by QSPI0SEL. Note: These bits are not retained when D1 power is turned off.
    0=Clock source from HXT; 1=Clock source from APLL0/2; 2=Clock source from PCLK0; 3=Clock source from HIRC; 4=Clock source from HIRC48M/4
0x448 CLK_SCSEL ro reset 0x22 — SC Clock Source Select Control Register
  [10:8] SC2SEL — SC2 Clock Source Selection. The peripheral clock source of SC2 is defined by SC2SEL. Note: These bits are not retained when D1 power is turned off.
    0=Clock source from HXT; 1=Clock source from APLL0/2; 2=Clock source from PCLK1; 3=Clock source from HIRC; 4=Clock source from HIRC48M/4
  [6:4] SC1SEL — SC1 Clock Source Selection. The peripheral clock source of SC1 is defined by SC1SEL. Note: These bits are not retained when D1 power is turned off.
    0=Clock source from HXT; 1=Clock source from APLL0/2; 2=Clock source from PCLK3; 3=Clock source from HIRC; 4=Clock source from HIRC48M/4
  [2:0] SC0SEL — SC0 Clock Source Selection. The peripheral clock source of SC0 is defined by SC0SEL. Note: These bits are not retained when D1 power is turned off.
    values as SC2SEL
0x44C CLK_SDHSEL ro reset 0x22 — SDH Clock Source Select Control Register
  [6:4] SDH1SEL — SDH1 Clock Source Selection. The peripheral clock source of SDH1 is defined by SDH1SEL. Note: These bits are not retained when D1 power is turned off.
    0=Clock source from HXT; 1=Clock source from APLL1/2; 2=Clock source from HCLK0; 3=Clock source from HIRC; 4=Clock source from HIRC48M/4
  [2:0] SDH0SEL — SDH0 Clock Source Selection. The peripheral clock source of SDH0 is defined by SDH0SEL. Note: These bits are not retained when D1 power is turned off.
    values as SDH1SEL
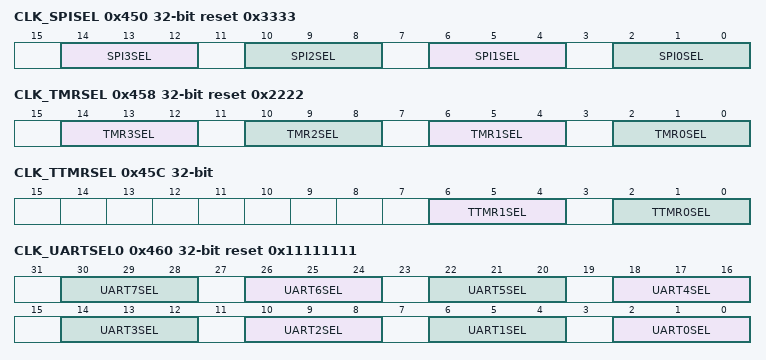
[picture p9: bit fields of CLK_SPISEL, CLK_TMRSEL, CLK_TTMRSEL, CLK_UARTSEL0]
0x450 CLK_SPISEL ro reset 0x3333 — SPI Clock Source Select Control Register
  [14:12] SPI3SEL — SPI3 Clock Source Selection. The peripheral clock source of SPI3 is defined by SPI3SEL. Note: These bits are not retained when D1 power is turned off.
    0=Clock source from HXT; 1=Clock source from APLL1/2; 2=Clock source from APLL0/2; 3=Clock source from PCLK2; 4=Clock source from HIRC; 5=Clock source from HIRC48M
  [10:8] SPI2SEL — SPI2 Clock Source Selection. The peripheral clock source of SPI2 is defined by SPI2SEL. Note: These bits are not retained when D1 power is turned off.
    0=Clock source from HXT; 1=Clock source from APLL1/2; 2=Clock source from APLL0/2; 3=Clock source from PCLK0; 4=Clock source from HIRC; 5=Clock source from HIRC48M
  [6:4] SPI1SEL — SPI1 Clock Source Selection. The peripheral clock source of SPI1 is defined by SPI1SEL. Note: These bits are not retained when D1 power is turned off.
    values as SPI3SEL
  [2:0] SPI0SEL — SPI0 Clock Source Selection. The peripheral clock source of SPI0 is defined by SPI0SEL. Note: These bits are not retained when D1 power is turned off.
    values as SPI2SEL
0x454 CLK_STSEL ro reset 0x2 — System Tick Clock Source Select Control Register
  [1:0] ST0SEL — Cortex-M55 SysTick 0 Clock Source Selection. Note 2: These bits are not retained when D0 power is turned off.
    0=Clock source from HXT; 1=Clock source from HXT/2; 2=Clock source from ACLK/2; 3=Clock source from HIRC/2
0x458 CLK_TMRSEL ro reset 0x2222 — Timer Clock Source Select Control Register
  [14:12] TMR3SEL — Timer 3 Clock Source Selection. The peripheral clock source of TMR3 is defined by TMR3SEL. Note: These bits are not retained when D1 power is turned off.
    0=Clock source from HXT; 1=Clock source from LXT; 2=Clock source from PCLK3; 3=Clock source from external clock TM3 pin; 4=Clock source from LIRC; 5=Clock source from HIRC; 6=Clock source from HIRC48M/4
  [10:8] TMR2SEL — Timer 2 Clock Source Selection. The peripheral clock source of TMR2 is defined by TMR2SEL. Note: These bits are not retained when D1 power is turned off.
    0=Clock source from HXT; 1=Clock source from LXT; 2=Clock source from PCLK3; 3=Clock source from external clock TM2 pin; 4=Clock source from LIRC; 5=Clock source from HIRC; 6=Clock source from HIRC48M/4
  [6:4] TMR1SEL — Timer 1 Clock Source Selection. The peripheral clock source of TMR1 is defined by TMR1SEL. Note: These bits are not retained when D1 power is turned off.
    0=Clock source from HXT; 1=Clock source from LXT; 2=Clock source from PCLK1; 3=Clock source from external clock TM1 pin; 4=Clock source from LIRC; 5=Clock source from HIRC; 6=Clock source from HIRC48M/4
  [2:0] TMR0SEL — Timer 0 Clock Source Selection. The peripheral clock source of TMR0 is defined by TMR0SEL. Note: These bits are not retained when D1 power is turned off.
    0=Clock source from HXT; 1=Clock source from LXT; 2=Clock source from PCLK1; 3=Clock source from external clock TM0 pin; 4=Clock source from LIRC; 5=Clock source from HIRC; 6=Clock source from HIRC48M/4
0x45C CLK_TTMRSEL ro — Tick Timer Clock Source Select Control Register
  [6:4] TTMR1SEL — Tick Timer 1 Clock Source Selection. The peripheral clock source of TTMR1 is defined by TTMR1SEL. Note: These bits are not retained when D2 power is turned off.
    0=Clock source from PCLK4; 1=Clock source from LXT; 2=Clock source from LIRC; 3=Clock source from MIRC; 4=Clock source from HIRC
  [2:0] TTMR0SEL — Tick Timer 0 Clock Source Selection. The peripheral clock source of TTMR0 is defined by TTMR0SEL. Note: These bits are not retained when D2 power is turned off.
    0=Clock source from PCLK2; 1=Clock source from LXT; 2=Clock source from LIRC; 3=Clock source from MIRC; 4=Clock source from HIRC
0x460 CLK_UARTSEL0 ro reset 0x11111111 — UART Clock Source Select Control Register 0
  [all] fields
    0=Clock source from HXT; 1=Clock source from HIRC; 2=Clock source from LXT; 3=Clock source from APLL0/2; 4=Clock source from HIRC48M
  [4n+2:4n] UART{n}SEL (n=0..7) — UART {n} Clock Source Selection. The peripheral clock source of UART{n} is defined by UART{n}SEL. Note: These bits are not retained when D1 power is turned off.
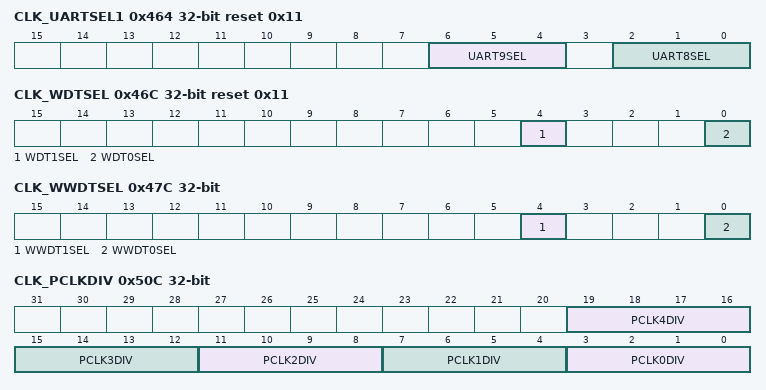
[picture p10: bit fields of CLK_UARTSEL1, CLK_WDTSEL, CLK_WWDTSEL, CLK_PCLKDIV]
0x464 CLK_UARTSEL1 ro reset 0x11 — UART Clock Source Select Control Register 1
  [6:4] UART9SEL — UART 9 Clock Source Selection. The peripheral clock source of UART9 is defined by UART9SEL. Note: These bits are not retained when D1 power is turned off.
    values as the fields of CLK_UARTSEL0
  [2:0] UART8SEL — UART 8 Clock Source Selection. The peripheral clock source of UART8 is defined by UART8SEL. Note: These bits are not retained when D1 power is turned off.
    values as the fields of CLK_UARTSEL0
0x468 CLK_USBSEL ro reset 0x1 — USB Clock Source Select Control Register
  [0] USBSEL — USB Clock Source Selection. The peripheral clock source of USBH, USBD and OTG is defined by USBSEL. Note: These bits are not retained when D1 power is turned off.
    0=Clock source from HIRC48M; 1=Clock source from APLL1/2
0x46C CLK_WDTSEL ro reset 0x11 — WDT Clock Source Select Control Register
  [4] WDT1SEL — WDT1 Clock Source Selection. The peripheral clock source of WDT1 is defined by WDT1SEL. Note: These bits are not retained when D2 power is turned off.
    0=Clock source from LXT; 1=Clock source from LIRC
  [0] WDT0SEL — WDT0 Clock Source Selection. The peripheral clock source of WDT0 is defined by WDT0SEL. Note: These bits are not retained when D2 power is turned off.
    0=Clock source from LXT; 1=Clock source from LIRC
0x47C CLK_WWDTSEL ro — WWDT Clock Source Select Control Register
  [4] WWDT1SEL — WWDT1 Clock Source Selection. Note: This bit is not retained when D0 power is turned off.
    0=Clock source from LIRC; 1=Clock source from LXT
  [0] WWDT0SEL — WWDT0 Clock Source Selection. Note: This bit is not retained when D0 power is turned off.
    0=Clock source from LIRC; 1=Clock source from LXT
0x500 CLK_SCLKDIV ro — SCLK Clock Divider Control Register
  [3:0] SCLKDIV — SCLK Clock Divide Number from SCLK Clock Source. Note: These bits are not retained when D2 power is turned off.
0x508 CLK_HCLKDIV ro — HCLK Clock Divider Control Register
  [11:8] HCLK2DIV — HCLK2 Clock Divide Number from HCLK2 Clock Source. Note: These bits are not retained when D2 power is turned off.
0x50C CLK_PCLKDIV ro — PCLK Clock Divider Control Register
  [4n+3:4n] PCLK{n}DIV (n=0..4) — PCLK{n} Clock Divide Number from PCLK{n} Clock Source. Note: These bits are not retained when D1 power is turned off.
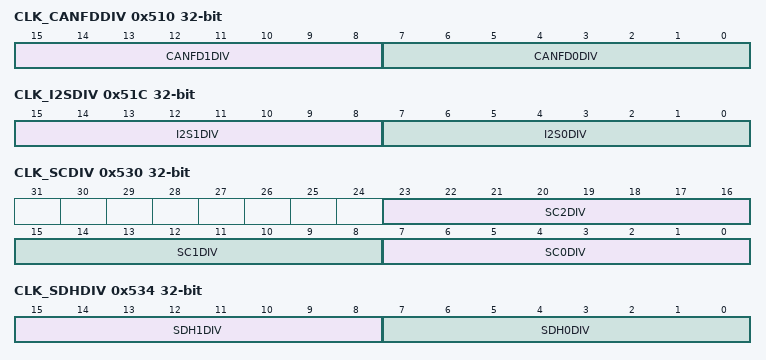
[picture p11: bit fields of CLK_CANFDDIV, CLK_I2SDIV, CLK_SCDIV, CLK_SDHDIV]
0x510 CLK_CANFDDIV ro — CANFD Clock Divider Control Register
  [15:8] CANFD1DIV — CANFD1 Clock Divide Number from CANFD1 Clock Source. Note: These bits are not retained when D1 power is turned off.
  [7:0] CANFD0DIV — CANFD0 Clock Divide Number from CANFD0 Clock Source. Note: These bits are not retained when D1 power is turned off.
0x514 CLK_DMICDIV ro — DMIC Clock Divider Control Register
  [7:0] DMIC0DIV — DMIC0 Clock Divide Number from DMIC0 Clock Source. Note: These bits are not retained when D2 power is turned off.
0x518 CLK_EADCDIV ro — EADC Clock Divider Control Register
  [7:0] EADC0DIV — EADC0 Clock Divide Number from EADC0 Clock Source. Note: These bits are not retained when D1 power is turned off.
0x51C CLK_I2SDIV ro — I2S Clock Divider Control Register
  [15:8] I2S1DIV — I2S1 Clock Divide Number from I2S1 Clock Source. Note: These bits are not retained when D1 power is turned off.
  [7:0] I2S0DIV — I2S0 Clock Divide Number from I2S0 Clock Source. Note: These bits are not retained when D1 power is turned off.
0x520 CLK_KPIDIV ro — KPI Clock Divider Control Register
  [7:0] KPI0DIV — KPI0 Clock Divide Number from KPI0 Clock Source. Note: These bits are not retained when D1 power is turned off.
0x524 CLK_LPADCDIV ro — Low Power ADC Clock Divider Control Register
  [7:0] LPADC0DIV — LPADC0 Clock Divide Number from LPADC0 Clock Source. Note: These bits are not retained when D2 power is turned off.
0x528 CLK_LPUARTDIV ro — Low Power UART Clock Divider Control Register
  [3:0] LPUART0DIV — LPUART0 Clock Divide Number from LPUART0 Clock Source. Note: These bits are not retained when D2 power is turned off.
0x52C CLK_PSIODIV ro — PSIO Clock Divider Control Register
  [7:0] PSIO0DIV — PSIO0 Clock Divide Number from PSIO0 Clock Source. Note: These bits are not retained when D1 power is turned off.
0x530 CLK_SCDIV ro — SC Clock Divider Control Register
  [23:16] SC2DIV — SC2 Clock Divide Number from SC2 Clock Source. Note: These bits are not retained when D1 power is turned off.
  [15:8] SC1DIV — SC1 Clock Divide Number from SC1 Clock Source. Note: These bits are not retained when D1 power is turned off.
  [7:0] SC0DIV — SC0 Clock Divide Number from SC0 Clock Source. Note: These bits are not retained when D1 power is turned off.
0x534 CLK_SDHDIV ro — SDH Clock Divider Control Register
  [15:8] SDH1DIV — SDH1 Clock Divide Number from SDH1 Clock Source. Note: These bits are not retained when D1 power is turned off.
  [7:0] SDH0DIV — SDH0 Clock Divide Number from SDH0 Clock Source. Note: These bits are not retained when D1 power is turned off.
0x538 CLK_STDIV ro — System Tick Clock Divider Control Register
  [7:0] ST0DIV — System Tick 0 Clock Divide Number from System Tick 0 Clock Source. Note: These bits are not retained when D0 power is turned off.
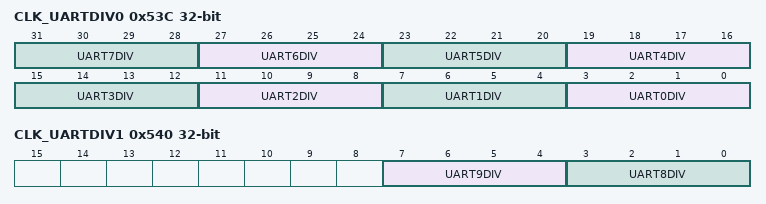
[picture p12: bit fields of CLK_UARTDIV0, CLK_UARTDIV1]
0x53C CLK_UARTDIV0 ro — UART Clock Divider Control Register 0
  [4n+3:4n] UART{n}DIV (n=0..7) — UART{n} Clock Divide Number from UART{n} Clock Source. Note: These bits are not retained when D1 power is turned off.
0x540 CLK_UARTDIV1 ro — UART Clock Divider Control Register 1
  [7:4] UART9DIV — UART9 Clock Divide Number from UART9 Clock Source. Note: These bits are not retained when D1 power is turned off.
  [3:0] UART8DIV — UART8 Clock Divide Number from UART8 Clock Source. Note: These bits are not retained when D1 power is turned off.
0x544 CLK_USBDIV ro — USB Clock Divider Control Register
  [3:0] USBDIV — USB Clock Divide Number from USB Clock Source. Note: These bits are not retained when D1 power is turned off.
0x548 CLK_VSENSEDIV ro — Video Pixel Clock Divider Control Register
  [3:0] VSENSEDIV — Video Pixel Clock Divide Number from Video Pixel Clock Source. Note: These bits are not retained when D2 power is turned off.
